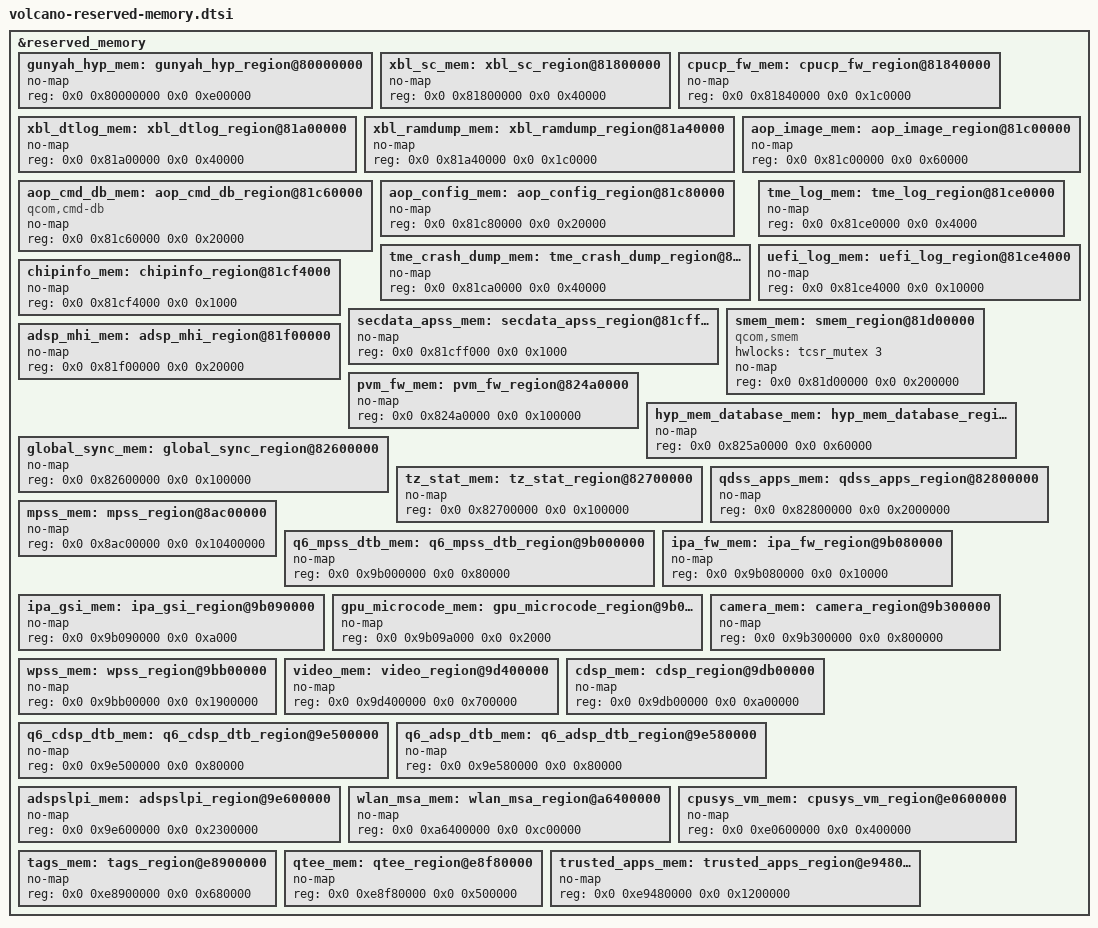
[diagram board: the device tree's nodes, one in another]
&reserved_memory {
	#address-cells = <2>;
	#size-cells = <2>;
	ranges;

	gunyah_hyp_mem: gunyah_hyp_region@80000000 {
		no-map;
		reg = <0x0 0x80000000 0x0 0xe00000>;
	};

	xbl_sc_mem: xbl_sc_region@81800000 {
		no-map;
		reg = <0x0 0x81800000 0x0 0x40000>;
	};

	cpucp_fw_mem: cpucp_fw_region@81840000 {
		no-map;
		reg = <0x0 0x81840000 0x0 0x1c0000>;
	};

	xbl_dtlog_mem: xbl_dtlog_region@81a00000 {
		no-map;
		reg = <0x0 0x81a00000 0x0 0x40000>;
	};

	xbl_ramdump_mem: xbl_ramdump_region@81a40000 {
		no-map;
		reg = <0x0 0x81a40000 0x0 0x1c0000>;
	};

	aop_image_mem: aop_image_region@81c00000 {
		no-map;
		reg = <0x0 0x81c00000 0x0 0x60000>;
	};

	aop_cmd_db_mem: aop_cmd_db_region@81c60000 {
		compatible = "qcom,cmd-db";
		no-map;
		reg = <0x0 0x81c60000 0x0 0x20000>;
	};

	aop_config_mem: aop_config_region@81c80000 {
		no-map;
		reg = <0x0 0x81c80000 0x0 0x20000>;
	};

	tme_crash_dump_mem: tme_crash_dump_region@81ca0000 {
		no-map;
		reg = <0x0 0x81ca0000 0x0 0x40000>;
	};

	tme_log_mem: tme_log_region@81ce0000 {
		no-map;
		reg = <0x0 0x81ce0000 0x0 0x4000>;
	};

	uefi_log_mem: uefi_log_region@81ce4000 {
		no-map;
		reg = <0x0 0x81ce4000 0x0 0x10000>;
	};

	chipinfo_mem: chipinfo_region@81cf4000 {
		no-map;
		reg = <0x0 0x81cf4000 0x0 0x1000>;
	};

	secdata_apss_mem: secdata_apss_region@81cff000 {
		no-map;
		reg = <0x0 0x81cff000 0x0 0x1000>;
	};

	smem_mem: smem_region@81d00000 {
		compatible = "qcom,smem";
		hwlocks = <&tcsr_mutex 3>;
		no-map;
		reg = <0x0 0x81d00000 0x0 0x200000>;
	};

	adsp_mhi_mem: adsp_mhi_region@81f00000 {
		no-map;
		reg = <0x0 0x81f00000 0x0 0x20000>;
	};

	pvm_fw_mem: pvm_fw_region@824a0000 {
		no-map;
		reg = <0x0 0x824a0000 0x0 0x100000>;
	};

	hyp_mem_database_mem: hyp_mem_database_region@825a0000 {
		no-map;
		reg = <0x0 0x825a0000 0x0 0x60000>;
	};

	global_sync_mem: global_sync_region@82600000 {
		no-map;
		reg = <0x0 0x82600000 0x0 0x100000>;
	};

	tz_stat_mem: tz_stat_region@82700000 {
		no-map;
		reg = <0x0 0x82700000 0x0 0x100000>;
	};

	qdss_apps_mem: qdss_apps_region@82800000 {
		no-map;
		reg = <0x0 0x82800000 0x0 0x2000000>;
	};

	mpss_mem: mpss_region@8ac00000 {
		no-map;
		reg = <0x0 0x8ac00000 0x0 0x10400000>;
	};

	q6_mpss_dtb_mem: q6_mpss_dtb_region@9b000000 {
		no-map;
		reg = <0x0 0x9b000000 0x0 0x80000>;
	};

	ipa_fw_mem: ipa_fw_region@9b080000 {
		no-map;
		reg = <0x0 0x9b080000 0x0 0x10000>;
	};

	ipa_gsi_mem: ipa_gsi_region@9b090000 {
		no-map;
		reg = <0x0 0x9b090000 0x0 0xa000>;
	};

	gpu_microcode_mem: gpu_microcode_region@9b09a000 {
		no-map;
		reg = <0x0 0x9b09a000 0x0 0x2000>;
	};

	camera_mem: camera_region@9b300000 {
		no-map;
		reg = <0x0 0x9b300000 0x0 0x800000>;
	};

	wpss_mem: wpss_region@9bb00000 {
		no-map;
		reg = <0x0 0x9bb00000 0x0 0x1900000>;
	};

	video_mem: video_region@9d400000 {
		no-map;
		reg = <0x0 0x9d400000 0x0 0x700000>;
	};

	cdsp_mem: cdsp_region@9db00000 {
		no-map;
		reg = <0x0 0x9db00000 0x0 0xa00000>;
	};

	q6_cdsp_dtb_mem: q6_cdsp_dtb_region@9e500000 {
		no-map;
		reg = <0x0 0x9e500000 0x0 0x80000>;
	};

	q6_adsp_dtb_mem: q6_adsp_dtb_region@9e580000 {
		no-map;
		reg = <0x0 0x9e580000 0x0 0x80000>;
	};

	adspslpi_mem: adspslpi_region@9e600000 {
		no-map;
		reg = <0x0 0x9e600000 0x0 0x2300000>;
	};

	wlan_msa_mem: wlan_msa_region@a6400000 {
		no-map;
		reg = <0x0 0xa6400000 0x0 0xc00000>;
	};

	cpusys_vm_mem: cpusys_vm_region@e0600000 {
		no-map;
		reg = <0x0 0xe0600000 0x0 0x400000>;
	};

	tags_mem: tags_region@e8900000 {
		no-map;
		reg = <0x0 0xe8900000 0x0 0x680000>;
	};

	qtee_mem: qtee_region@e8f80000 {
		no-map;
		reg = <0x0 0xe8f80000 0x0 0x500000>;
	};

	trusted_apps_mem: trusted_apps_region@e9480000 {
		no-map;
		reg = <0x0 0xe9480000 0x0 0x1200000>;
	};

};
